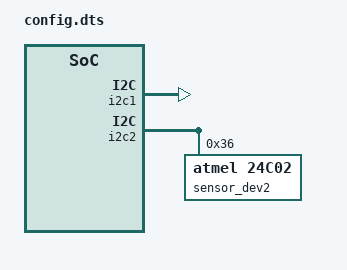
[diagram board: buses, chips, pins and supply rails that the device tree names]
/dts-v1/;

#include "src/peripherals/official_plugins/microchip_at24c02c/at24c02c.dtsi"

/ {
    /* 
     * 【解説: I2Cバス0の定義】
     * ベースアドレス 0xe0004000 にある Cadence I2C コントローラを定義します。
     * スレーブデバイス (eeprom@50) はベンダー提供の at24c02c.dtsi を #include して配置します。
     */
    i2c1: i2c@e0004000 {
        compatible = "cdns,i2c-r1p10";
        reg = <0xe0004000 0x1000>;
        bus_id = <0>;
        label = "/dev/i2c-0";
    };

    /* 
     * 【解説: I2Cバス1の定義】
     * 物理的に別の場所にある、もう一つの I2C コントローラを定義します。
     */
    i2c2: i2c@e0005000 {
        compatible = "cdns,i2c-r1p10";
        reg = <0xe0005000 0x1000>;
        bus_id = <1>;
        label = "/dev/i2c-1";

        /*
         * 【解説: スレーブデバイスの定義（I2Cバス1配下）】
         * - sensor_dev2: ラベル
         * - sensor@36: ノード名（デバイス種類 @ I2Cスレーブアドレス）
         * - compatible: 互換性ドライバ名
         * - reg: スレーブアドレス (0x36)
         * - fbb,mock-data: エミュレータ返却の初期値データ (0x20)
         */
        sensor_dev2: sensor@36 {
            compatible = "atmel,24c02";
            reg = <0x36>;
            fbb,mock-data = <0x20>;
        };
    };
};
